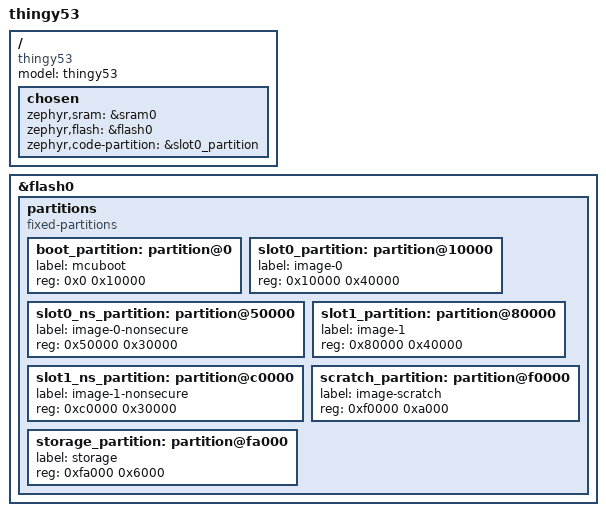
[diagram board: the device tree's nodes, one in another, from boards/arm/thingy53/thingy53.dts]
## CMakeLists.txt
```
#
# Copyright (c) 2019 Nordic Semiconductor ASA
#
# SPDX-License-Identifier: LicenseRef-Nordic-5-Clause
#
cmake_minimum_required(VERSION 3.20.0)

set(PM_STATIC_YML_FILE
  ${CMAKE_CURRENT_SOURCE_DIR}/boards/pm_static_${BOARD}.yml
  )

find_package(Zephyr REQUIRED HINTS $ENV{ZEPHYR_BASE})
project(bdi-coap-client)


FILE(GLOB APP_SOURCES src/main.cpp
         src/coap/CoapClient.cpp
         src/mas-abstractions/organization/Organization.cpp
         src/mas-abstractions/agent/ReactiveAgent.cpp
         src/thread/thread_helper.c
         src/peripherals/gpio.c
         src/low_power.c
         src/observer.c)

#FILE(GLOB EMB_BDI_AGENT_SOURCES embedded-bdi/lib/agent/*.cpp)
#FILE(GLOB EMB_BDI_BDI_SOURCES embedded-bdi/lib/bdi/*.cpp)
#FILE(GLOB EMB_BDI_LIB_SOURCES embedded-bdi/lib/lib/*.cpp)
#FILE(GLOB EMB_BDI_SYNTAX_SOURCES embedded-bdi/lib/syntax/*.cpp)

# NORDIC SDK APP START

# Using Embedded BDI (Uncomment following two lines)
#target_sources(app PRIVATE ${APP_SOURCES} ${EMB_BDI_AGENT_SOURCES} ${EMB_BDI_BDI_SOURCES} ${EMB_BDI_LIB_SOURCES} ${EMB_BDI_SYNTAX_SOURCES})
#target_include_directories(app PRIVATE src embedded-bdi embedded-bdi/lib interface)

# Using Reactive Agent
target_sources(app PRIVATE ${APP_SOURCES})
target_include_directories(app PRIVATE src interface)


# Preinitialization related to Thingy:53 DFU
#target_sources_ifdef(CONFIG_BOARD_THINGY53_NRF5340_CPUAPP app PRIVATE
#  boards/thingy53.c
#)
#target_sources_ifdef(CONFIG_BOARD_THINGY53_NRF5340_CPUAPP_NS app PRIVATE
#  boards/thingy53.c
#)

# NORDIC SDK APP END

target_sources_ifdef(CONFIG_BT_NUS app PRIVATE src/ble_utils.c)
zephyr_library_include_directories(.)
```

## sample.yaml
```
sample:
  description: Thingy:53 BDI CoAP Client Application
  name: Thingy:53 BDI CoAP Client
tests:
  applications.openthread.thingy53-bdi-coap-client:
    build_only: true
    integration_platforms:
      - thingy53_nrf5340_cpuapp
      - thingy53_nrf5340_cpuapp_ns
    platform_allow: thingy53_nrf5340_cpuapp thingy53_nrf5340_cpuapp_ns
    tags: openthread ci_build
```

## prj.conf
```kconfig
################################################################################
# Nordic related
CONFIG_NCS_SAMPLES_DEFAULTS=n
# nRF board library
CONFIG_DK_LIBRARY=y
#CONFIG_OPENTHREAD_NORDIC_LIBRARY_MASTER=y

################################################################################
# Logging related
#CONFIG_SERIAL=n
CONFIG_LOG=y
CONFIG_CONSOLE=y
CONFIG_UART_CONSOLE=y
CONFIG_RTT_CONSOLE=y
CONFIG_USE_SEGGER_RTT=y
CONFIG_PRINTK=y
CONFIG_LOG_MODE_IMMEDIATE=n
CONFIG_STDOUT_CONSOLE=y
#CONFIG_SHELL_BACKEND_RTT=y

################################################################################
# PM related 
#Low power config
#CONFIG_PM=y
CONFIG_PM_DEVICE=y
CONFIG_CRC=y
CONFIG_POWEROFF=y

# Network shell
#CONFIG_SHELL=y
#CONFIG_OPENTHREAD_SHELL=y
#CONFIG_SHELL_ARGC_MAX=26
#CONFIG_SHELL_CMD_BUFF_SIZE=416

# Network sockets
CONFIG_NET_SOCKETS=y
CONFIG_NET_SOCKETS_POSIX_NAMES=y
CONFIG_NET_SOCKETS_POLL_MAX=4

#######################################################################
CONFIG_BT=y
CONFIG_BT_OBSERVER=y

################################################################################
#OpenThread related --------------------------------------------------------------
# Same network Master Key for client and server
CONFIG_OPENTHREAD_NETWORKKEY="00:11:22:33:44:55:66:77:88:99:aa:bb:cc:dd:ee:ff"
# L2 OpenThread enabling
CONFIG_NET_L2_OPENTHREAD=y
# Generic networking options
CONFIG_NETWORKING=y
CONFIG_OPENTHREAD_SHELL=n
CONFIG_OPENTHREAD_MTD=y
CONFIG_OPENTHREAD_MTD_SED=y
CONFIG_OPENTHREAD_POLL_PERIOD=3000

#CONFIG_OPENTHREAD_MTD = y
#CONFIG_OPENTHREAD = y
#CONFIG_OPENTHREAD_MTD_SED=y
#CONFIG_OPENTHREAD_POLL_PERIOD=600000
# Enable OpenThread CoAP support API
CONFIG_OPENTHREAD_COAP=y
#CONFIG_COAP_UTILS=y
CONFIG_OPENTHREAD_COAP_BLOCK=y
CONFIG_OPENTHREAD_COAP_OBSERVE=y
#CONFIG_COAP_CLIENT_LOG_LEVEL_DBG=y
#CONFIG_COAP_CLIENT_UTILS_LOG_LEVEL_DBG=y
#CONFIG_COAP_UTILS_LOG_LEVEL_DBG=y
CONFIG_OPENTHREAD_LOG_LEVEL_NOTE=y
CONFIG_OPENTHREAD_DEBUG=y

################################################################################
CONFIG_ASSERT=y
CONFIG_ASSERT_NO_COND_INFO=y
CONFIG_MBEDTLS_SHA1_C=n
CONFIG_FPU=y

CONFIG_NEWLIB_LIBC=y
CONFIG_CPLUSPLUS=y
CONFIG_STD_CPP20=n
CONFIG_LIB_CPLUSPLUS=y


################################################################################
# Stack configuration

CONFIG_HEAP_MEM_POOL_SIZE=3600
CONFIG_SYSTEM_WORKQUEUE_STACK_SIZE=4096
CONFIG_MAIN_STACK_SIZE=4096

################################################################################
# Sensor configuration

# Enable BME688 Sensor
CONFIG_BME680=y
CONFIG_I2C=y
CONFIG_SPI=y
CONFIG_SENSOR=y
CONFIG_CBPRINTF_FP_SUPPORT=y
# Disable nRF5 sensor
CONFIG_TEMP_NRF5=n
# Battery Options
#CONFIG_ADC=y

################################################################################
# Extra libraries
CONFIG_JSON_LIBRARY=y
```

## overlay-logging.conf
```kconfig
#
# Copyright (c) 2022 Nordic Semiconductor
#
# SPDX-License-Identifier: LicenseRef-Nordic-5-Clause

# Enable net module logging
CONFIG_NET_LOG=y
# Option for configuring log level in net config library
CONFIG_NET_CONFIG_LOG_LEVEL_INF=y

# Option for configuring log level in Zephyr L2 logging
CONFIG_OPENTHREAD_L2_DEBUG=y
CONFIG_OPENTHREAD_L2_LOG_LEVEL_DBG=y
CONFIG_OPENTHREAD_L2_DEBUG_DUMP_15_4=y
CONFIG_OPENTHREAD_L2_DEBUG_DUMP_IPV6=y

# Option for configuring log level in OpenThread
CONFIG_OPENTHREAD_LOG_LEVEL_INFO=y
```

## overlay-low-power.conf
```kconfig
#
# Copyright (c) 2022 Nordic Semiconductor
#
# SPDX-License-Identifier: LicenseRef-Nordic-5-Clause
#

CONFIG_LOG=n
CONFIG_PRINTK=n
CONFIG_OPENTHREAD_NORDIC_LIBRARY_MTD=y
CONFIG_OPENTHREAD_MTD=y
CONFIG_RAM_POWER_DOWN_LIBRARY=y
CONFIG_PM_DEVICE=y

CONFIG_SYSTEM_WORKQUEUE_STACK_SIZE=2048
```

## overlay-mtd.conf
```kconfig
#
# Copyright (c) 2020 Nordic Semiconductor
#
# SPDX-License-Identifier: LicenseRef-Nordic-5-Clause
#

# Enable MTD Sleepy End Device
CONFIG_OPENTHREAD_MTD=y
CONFIG_OPENTHREAD_MTD_SED=y
CONFIG_OPENTHREAD_POLL_PERIOD=3000
CONFIG_RAM_POWER_DOWN_LIBRARY=y
CONFIG_PM_DEVICE=y
```

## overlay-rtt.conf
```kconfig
#
# Copyright (c) 2022 Nordic Semiconductor
#
# SPDX-License-Identifier: LicenseRef-Nordic-5-Clause
#

# Disable RTT logging backend
CONFIG_USE_SEGGER_RTT=y
CONFIG_LOG_BACKEND_RTT=y

# Enable UART logging backend
CONFIG_LOG_BACKEND_UART=n
CONFIG_SHELL_LOG_BACKEND=n
```

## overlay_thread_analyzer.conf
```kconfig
#
# Copyright (c) 2020 Nordic Semiconductor
#
# SPDX-License-Identifier: LicenseRef-Nordic-5-Clause
#
#


# In order to correctly tune the stack sizes for the threads the following
# Configurations can enabled to print the current use:
CONFIG_THREAD_NAME=y
CONFIG_THREAD_ANALYZER=y
CONFIG_THREAD_ANALYZER_AUTO=y
CONFIG_THREAD_ANALYZER_RUN_UNLOCKED=y
CONFIG_THREAD_ANALYZER_USE_PRINTK=y
CONFIG_CONSOLE=y
CONFIG_UART_CONSOLE=y
CONFIG_SERIAL=y
CONFIG_PRINTK=y
```

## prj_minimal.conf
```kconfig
#
# Copyright (c) 2020 Nordic Semiconductor
#
# SPDX-License-Identifier: LicenseRef-Nordic-5-Clause
#
#
CONFIG_NCS_SAMPLES_DEFAULTS=y
# nRF board library
CONFIG_DK_LIBRARY=y

# Enable OpenThread CoAP support API
CONFIG_OPENTHREAD_COAP=y
#CONFIG_COAP_UTILS=y
CONFIG_OPENTHREAD_COAP_BLOCK=y
CONFIG_OPENTHREAD_COAP_OBSERVE=y

# Configure sample logging setting
CONFIG_LOG=n
CONFIG_COAP_CLIENT_LOG_LEVEL_DBG=n
CONFIG_COAP_CLIENT_UTILS_LOG_LEVEL_DBG=n
#CONFIG_COAP_UTILS_LOG_LEVEL_DBG=y
CONFIG_OPENTHREAD_LOG_LEVEL_NOTE=n
CONFIG_OPENTHREAD_DEBUG=n

# Adjust log strdup settings

# Network shell
CONFIG_SHELL=y
CONFIG_OPENTHREAD_SHELL=y
CONFIG_SHELL_ARGC_MAX=26
CONFIG_SHELL_CMD_BUFF_SIZE=416

# Network sockets
CONFIG_NET_SOCKETS=y
CONFIG_NET_SOCKETS_POSIX_NAMES=y
CONFIG_NET_SOCKETS_POLL_MAX=4

# Same network Master Key for client and server
CONFIG_OPENTHREAD_NETWORKKEY="00:11:22:33:44:55:66:77:88:99:aa:bb:cc:dd:ee:ff"

# L2 OpenThread enabling
CONFIG_NET_L2_OPENTHREAD=y

# Generic networking options
CONFIG_NETWORKING=y

CONFIG_ASSERT=y
CONFIG_ASSERT_NO_COND_INFO=y
CONFIG_MBEDTLS_SHA1_C=n
CONFIG_FPU=y

CONFIG_PRINTK=y
CONFIG_NEWLIB_LIBC=y
CONFIG_CPLUSPLUS=y
CONFIG_STD_CPP20=n
CONFIG_LIB_CPLUSPLUS=y


################################################################################
# Stack configuration

CONFIG_HEAP_MEM_POOL_SIZE=3600
CONFIG_SYSTEM_WORKQUEUE_STACK_SIZE=4096
CONFIG_MAIN_STACK_SIZE=4096

################################################################################
# Sensor configuration

# Enable BME688 Sensor
CONFIG_BME680=y

CONFIG_I2C=y
CONFIG_SPI=y
CONFIG_SENSOR=y
CONFIG_CBPRINTF_FP_SUPPORT=y

# Disable nRF5 sensor
CONFIG_TEMP_NRF5=n

# Battery Options
#CONFIG_ADC=y

################################################################################
# PM related 
#Low power config
#CONFIG_PM=y
CONFIG_PM_DEVICE=y
CONFIG_CRC=y
CONFIG_POWEROFF=y

################################################################################
# Extra libraries
CONFIG_JSON_LIBRARY=y
```

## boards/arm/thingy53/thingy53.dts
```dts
// Copyright (c) 2023 Nordic Semiconductor ASA
// SPDX-License-Identifier: Apache-2.0

/dts-v1/;
#include <nordic/nrf5340_cpuapp_qkaa.dtsi>

/ {
	model = "thingy53";
	compatible = "thingy53";

	chosen {
		zephyr,sram = &sram0;
		zephyr,flash = &flash0;
		zephyr,code-partition = &slot0_partition;
	};
};

&flash0 {
	partitions {
		compatible = "fixed-partitions";
		#address-cells = <1>;
		#size-cells = <1>;

		boot_partition: partition@0 {
			label = "mcuboot";
			reg = <0x0 0x10000>;
		};
		slot0_partition: partition@10000 {
			label = "image-0";
			reg = <0x10000 0x40000>;
		};
		slot0_ns_partition: partition@50000 {
			label = "image-0-nonsecure";
			reg = <0x50000 0x30000>;
		};
		slot1_partition: partition@80000 {
			label = "image-1";
			reg = <0x80000 0x40000>;
		};
		slot1_ns_partition: partition@c0000 {
			label = "image-1-nonsecure";
			reg = <0xc0000 0x30000>;
		};
		scratch_partition: partition@f0000 {
			label = "image-scratch";
			reg = <0xf0000 0xa000>;
		};
		storage_partition: partition@fa000 {
			label = "storage";
			reg = <0xfa000 0x6000>;
		};
	};
};
```

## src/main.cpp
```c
/**
 * Thing:53 BDI CoAP Client
 *
 * main.cpp
 */

#include <dk_buttons_and_leds.h>
#include <ram_pwrdn.h>
#include <zephyr/pm/device.h>
#include <zephyr/pm/pm.h>
//#include <zephyr/drivers/gpio.h>
#include <zephyr/sys/poweroff.h>
#include <ram_pwrdn.h>

#include "main.h"
#include "mas-abstractions/organization/Organization.h"
#include "mas-abstractions/agent/ReactiveAgent.h"

#define CONFIG_THINGY_LOW_POWER
//#define CONFIG_THINGY_USE_SENSOR
#if defined(CONFIG_THINGY_LOW_POWER)
#include "low_power.h"
#endif

#include <zephyr/bluetooth/bluetooth.h>
#include "observer.c"

LOG_MODULE_REGISTER(main, CONFIG_COAP_CLIENT_LOG_LEVEL);

//#define GPIO0_NODE DT_NODELABEL(gpio0)
//#define PIN 9

/**************************************************************************************************
  Agent ID string.
**************************************************************************************************/
std::string agent_id = "agent-" + std::to_string(AGENT_ID);

/**************************************************************************************************
  LED defines.
**************************************************************************************************/
#define RED_LED				DK_LED1
#define GREEN_LED			DK_LED2
#define BLUE_LED			DK_LED3


/**************************************************************************************************
  Variables for BDI-reasoner
**************************************************************************************************/
int32_t agent_period = DEFAULT_AGENT_PERIOD;
//

/**************************************************************************************************
  Global Variables.
**************************************************************************************************/

/**************************************************************************************************
  CoAP Variables.
**************************************************************************************************/
#ifdef CONFIG_THINGY_USE_SENSOR
BME688* m_p_bme_sensor;
#endif
#ifdef USE_EMB_BDI
	Agent* m_p_sensor_agent;
#else
	ReactiveAgent* m_p_sensor_agent;
#endif
/**************************************************************************************************
  Thread Declarations.
**************************************************************************************************/

/**************************************************************************************************
  Embedded BDI Agent Thread Declaration.
**************************************************************************************************/
void agent_run_thread_cb(void);
K_THREAD_DEFINE(agent_run_thread_id, STACKSIZE, agent_run_thread_cb, NULL, NULL, NULL, 
					AGENT_PRIORITY, 0, 0);

/**************************************************************************************************
  Measurement Thread Declaration.
**************************************************************************************************/
void sensing_thread_cb(void);
K_THREAD_DEFINE(sensing_thread_id, SENSING_STACKSIZE, sensing_thread_cb, NULL, NULL, NULL, 
					SENSOR_PRIORITY, 0, 0);

/**************************************************************************************************
  Transmission Thread Declaration.
**************************************************************************************************/
void transmission_thread_cb(void);
K_THREAD_DEFINE(transmission_thread_id, TRANSMISSION_STACKSIZE, transmission_thread_cb, NULL, NULL, NULL, 
					TRANSMISSION_PRIORITY, 0, 0);


/**************************************************************************************************
  BDI Callback-Functions.
**************************************************************************************************/


/**************************************************************************************************
  OpenThread Callback-Functions.
**************************************************************************************************/

/**************************************************************************************************
  Toggles MED and SED mode when enabled in build.
**************************************************************************************************/
//typedef struct otLinkModeConfig
//{
//    bool mRxOnWhenIdle : 1; ///< 1, if the sender has its receiver on when not transmitting. 0, otherwise.
//    bool mDeviceType : 1;   ///< 1, if the sender is an FTD. 0, otherwise.
//    bool mNetworkData : 1;  ///< 1, if the sender requires the full Network Data. 0, otherwise.
//}

static void on_mtd_mode_toggle(/*uint32_t med*/otLinkModeConfig mode)
{
#if IS_ENABLED(CONFIG_PM_DEVICE)
	const struct device *cons = DEVICE_DT_GET(DT_CHOSEN(zephyr_console));

	if (!device_is_ready(cons)) {
		return;
	}
	uint32_t rxon = mode.mRxOnWhenIdle;
	uint32_t ftd = mode.mDeviceType;
	dk_set_led_off(BLUE_LED);
	dk_set_led_off(RED_LED);
	dk_set_led_off(GREEN_LED);
	if (rxon || ftd) {
		// pm_device_action_run(cons, PM_DEVICE_ACTION_RESUME);
		dk_set_led_on(RED_LED);
	} else {
		// pm_device_action_run(cons, PM_DEVICE_ACTION_SUSPEND);
		dk_set_led_on(GREEN_LED);
	}
#endif
	
}

/**************************************************************************************************
  Button Actions.
**************************************************************************************************/
static bool in_role = false;
static void on_button_changed(uint32_t button_state, uint32_t has_changed)
{
	uint32_t buttons = button_state & has_changed;
	if ((buttons & DK_BTN1_MSK) && has_changed==1) {
		dk_set_led_off(BLUE_LED);
		dk_set_led_off(RED_LED);
		dk_set_led_off(GREEN_LED);

		
		//LOG_INF("Creating organization entity object %d", 2);
		if(in_role){
			Organization::leaveRole("rl-1");
			dk_set_led_on(RED_LED);
			in_role = false;
		}else{
			Organization::joinRole("rl-1", 100);
			dk_set_led_on(GREEN_LED);
			in_role = true;
		}
		//Organization::sendMeasurement("gr_test_role", 12.1);
	}else if (buttons & DK_BTN2_MSK) {
		// Nothing

	}
}

/**************************************************************************************************
  Sensor Semaphore.
**************************************************************************************************/
K_SEM_DEFINE(sensor_sem, 0, 1);

/**************************************************************************************************
  Sensing Thread. Lower number -> higher prio
**************************************************************************************************/
void sensing_thread_cb(void)
{
	k_sleep(K_FOREVER);
	/* Run sensing loop */
	while(true){
		/* Sleep as long as no role is assigned */
		//LOG_INF("%i: Sensing Thread...\n", log_iterator++);
		/* Read BME688 enviromental sensor */		
		#ifdef CONFIG_THINGY_USE_SENSOR
		m_p_bme_sensor->measure();

		/* Release transmission when buffer is full */
		if (m_p_bme_sensor->isBufferFull())
		{ 
			k_sem_give(&sensor_sem);
		}
		#endif
		/* sleep */
		//k_sleep(1000 /*roles[current_role].getMeasurementPeriod()*/);
	}
}

/**************************************************************************************************
  Transmission Thread.
**************************************************************************************************/
void transmission_thread_cb(void)
{
	//k_sleep(K_FOREVER);
	/* Run transmission loop */
	while(true){
		/* Transmit to Server */
		k_sem_take(&sensor_sem, K_FOREVER); //Add timeout to prevent deadlock...
		//LOG_INF("%i: Transmit sensor data:\n---> %s\n", log_iterator++, m_p_bme_sensor->getPayload() .c_str());

		/* Reset buffer */
		#ifdef CONFIG_THINGY_USE_SENSOR
		m_p_bme_sensor->clearBuffer();
		#endif
		/* sleep */
		k_sleep(K_FOREVER);
	}
}

/**************************************************************************************************
  Embedded BDI Agent Thread.
**************************************************************************************************/
void agent_run_thread_cb(void)
{
	k_sleep(K_FOREVER);
	while(true){
		LOG_INF("%s","Waking agent..");
		dk_set_led_off(BLUE_LED);
		dk_set_led_off(RED_LED);
		dk_set_led_on(GREEN_LED);
		m_p_sensor_agent->run();
		k_msleep(agent_period);
	}
}

/**************************************************************************************************
  Main Function.
**************************************************************************************************/
int main(void)
{
	LOG_INF("%i: Start Thingy:53 BDI CoAP Client...\n", log_iterator++);

	int ret;
	#if USE_GPIO_OUTPUT
		/* Initialize GPIOs */
		ret = gpio_output_init();
		if (ret) {
			LOG_ERR("Cannot init gpios, (error: %d)", ret);
			return 0;
		}
		gpio_pin_set_dt(&out0, 0);
		gpio_pin_set_dt(&out1, 0);
		gpio_pin_set_dt(&out2, 0);
	#endif /* USE_GPIO_OUTPUT */



	//struct otInstance *openthread = openthread_get_default_instance();
	//struct net_if * net = net_if_get_default();

	/* Enabled if built as sleepy end device */
	if (IS_ENABLED(CONFIG_RAM_POWER_DOWN_LIBRARY)) {
		//power_down_unused_ram();
	}

	/* Initialize buttons */
	ret = dk_buttons_init(on_button_changed);
	if (ret) {
		LOG_ERR("Cannot init buttons (error: %d)", ret);
		return 0;
	}

	/* Initialize LEDs */
	ret = dk_leds_init();
	if (ret) {
		LOG_ERR("Cannot init leds, (error: %d)", ret);
		return 0;
	}

	/* Initialize Sensor object*/
	#ifdef CONFIG_THINGY_USE_SENSOR
	m_p_bme_sensor = new BME688(agent_id);
	#endif
	m_p_sensor_agent = new ReactiveAgent();
	/* Initialize battery measurement */
	//ret = battery_measure_enable(true);
	//if (ret) {
	//	LOG_ERR("Failed initialize battery measurement (error: %d)", ret);
	//	return 0;
	//}

	LOG_INF("Creating CoAP channel %d",1);
	//LOG_INF("CoAP channel initialized. Response=%d", resp);
	dk_set_led_off(BLUE_LED);
	dk_set_led_off(RED_LED);
	dk_set_led_off(GREEN_LED);
	startThread(on_mtd_mode_toggle);	
	k_sleep(K_MSEC(2000));



	
	CoapClient::initialize();
	//dk_set_led_on(BLUE_LED);
	//k_sleep(K_MSEC(2000));
	//dk_set_led_off(BLUE_LED);
	//dk_set_led_off(RED_LED);
	//dk_set_led_off(GREEN_LED);


	printk("Starting Observer Demo\n");

	/* Initialize the Bluetooth Subsystem */
	int err = bt_enable(NULL);
	if (err) {
		printk("Bluetooth init failed (err %d)\n", err);
		return 0;
	}

	(void)observer_start();

#if defined(CONFIG_THINGY_LOW_POWER)
	//low_power_enable();
#endif


	while(true){
		dk_set_led_on(BLUE_LED);
		k_sleep(K_MSEC(500));
		dk_set_led_off(BLUE_LED);
		//k_sleep(K_MSEC(500));
		//dk_set_led_off(BLUE_LED);
		//dk_set_led_off(RED_LED);

		//dk_set_led_off(GREEN_LED);
			
		//gpio_output_set(9,1); //Trace to mark energy measurement start	
		Organization::refresh();
		//m_p_sensor_agent->run();S
		k_sleep(K_MSEC(1000));
		LOG_INF("ding %d ",1);
		printk("ding..");
	}

}
```

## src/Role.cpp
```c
#include "Role.h"
/**************************************************************************************************
  Role Class.
**************************************************************************************************/
Role::Role(int role_number, const char *org_spec, std::string agent_id) {
	get_group_and_role_id(role_number, &m_group_id, &m_role_id, &m_group_number, org_spec);
	m_role_number = role_number;
	get_role_property(m_role_id, "update_period", &m_update_period, org_spec);
	get_role_property(m_role_id, "measurement_period", &m_measurement_period, org_spec);
	get_group_spec(m_role_id, "min", &m_min_agents, org_spec);
	m_workload_divider = 1;
	m_role_costs = 0;
	reevaluateRoleCosts(false,1);
    m_agent_id = agent_id;
}

void Role::setOrgSpecReward(int reward)
{
	m_org_spec_reward = reward;
	return;
}

void Role::reevaluateRoleCosts(bool override, int battery)
{    
    if(!override){
		//update_battery_level(&m_battery_level);
	}else{
		m_battery_level = battery;
	}
	/* Lower Frequency */
	if (30 < m_measurement_period) {
		m_role_costs = m_battery_level == 1 ? -1 : 0;
	}
	else if (m_measurement_period <= 30) {
		m_role_costs = m_battery_level == 1 ? 0 : 2;
	}
	return;
}

void Role::setWorkloadDivider(int number_of_agents)
{
	m_workload_divider = number_of_agents;
	return;
}

int Role::getTotalCostReward()
{
	return m_org_spec_reward-m_role_costs;
}

int Role::getRoleNumber()
{
	return m_role_number;
}

std::string Role::getRoleId()
{
	return m_role_id;
}

std::string Role::getRoleUri()
{
	std::string uri = "org-entities/oe-groups/gr_0" + std::to_string(m_group_number) + "_" +
	m_group_id + "/gr_0" + std::to_string(m_group_number) + "_" + m_group_id + "_" + m_role_id;
	return uri;
}

std::string Role::getRolePlayerUri()
{
	std::string uri = "org-entities/oe-groups/gr_0" + std::to_string(m_group_number) + "_" +
	m_group_id + "/gr_0" + std::to_string(m_group_number) + "_" + m_group_id + "_" + m_role_id;
	
	uri = uri + "/" + "rp_" + m_agent_id + "_gr_0" + std::to_string(m_group_number) + "_" +
	m_group_id + "_" + m_role_id;
	return uri;
}

int Role::getBufferSize(){
	return m_update_period/m_measurement_period;
}

k_timeout_t Role::getMeasurementPeriod(){
	return K_MSEC(m_workload_divider*m_measurement_period*1000);
}

int Role::getWorkloadDivider()
{
	return m_workload_divider;
}
```

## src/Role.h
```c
#ifndef ROLE2_H
#define ROLE2_H

#include <stdio.h>
#include <stdlib.h>
#include <unistd.h>
#include <vector>
#include <array>
#include <string>
#include <iostream>
#include <math.h>
#include <numeric>
#include <algorithm>

/**************************************************************************************************
  ZEPHYR include files.
**************************************************************************************************/
#include <zephyr/kernel.h>



/**************************************************************************************************
  Task include files.
**************************************************************************************************/
#include "agent/agent.h"
#include "config/configuration.h"
#include "bdi-agent/functions.h"
#include "parse_xml.h"
#include <coap_server_client_interface.h>

extern "C" {
  #include "coap_client_utils.h"
  //#include "sensors.h"
  //#include "battery.h"
  //#include "gpio.h"
}

/**************************************************************************************************
  Role Class.
**************************************************************************************************/
class Role {
	private:
		std::string m_group_id;
		std::string m_role_id;
		int m_group_number;
		int m_role_number;
		int m_measurement_period;
		int m_update_period;
		int m_role_costs;
		int m_org_spec_reward;
		int m_min_agents;
		int m_workload_divider;
        int m_battery_level = 1;
        std::string m_agent_id;

	public:
		Role(int role_number, const char *org_spec, std::string agent_id);
		void setOrgSpecReward(int reward);
		void reevaluateRoleCosts(bool override, int battery);
		void setWorkloadDivider(int number_of_agents);
		std::string getRoleId();
		int getRoleNumber();
		std::string getRoleUri();
		std::string getRolePlayerUri();
		int getTotalCostReward();
		int getBufferSize();
		int getWorkloadDivider();
		k_timeout_t getMeasurementPeriod();
};
#endif
```

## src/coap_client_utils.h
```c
/**
 * coap_client_utils.h
 */

#ifndef __COAP_CLIENT_UTILS_H__
#define __COAP_CLIENT_UTILS_H__

#include <coap_server_client_interface.h>

/** @brief Type indicates function called when OpenThread connection
 *         is established.
 *
 * @param[in] item pointer to work item.
 */
typedef void (*ot_connection_cb_t)(struct k_work *item);

/** @brief Type indicates function called when OpenThread connection is ended.
 *
 * @param[in] item pointer to work item.
 */
typedef void (*ot_disconnection_cb_t)(struct k_work *item);

/** @brief Type indicates function called when the MTD modes are toggled.
 *
 * @param[in] val 1 if the MTD is in MED mode
 *                0 if the MTD is in SED mode
 */
typedef void (*mtd_mode_toggle_cb_t)(uint32_t val);

typedef void (*get_org_spec_xml_cb_t)(uint8_t *data, uint16_t size, uint8_t xml_part, uint8_t total_xml_parts);

typedef void (*post_role_cb_t)(bool created);

typedef void (*delete_role_cb_t)(bool success);

typedef void (*get_reward_cb_t)(int reward, const char *role_id, bool role_player);


/** @brief Initialize CoAP client utilities.
 */
int coap_client_utils_init(ot_connection_cb_t on_connect,
			    ot_disconnection_cb_t on_disconnect,
			    mtd_mode_toggle_cb_t on_toggle,
				get_org_spec_xml_cb_t on_get_xml,
				post_role_cb_t on_post_role,
				delete_role_cb_t on_delete_role,
				get_reward_cb_t on_get_reward);

/**************************************************************************************************
  Initializes GET organizational specification XML request to CoAP server.
**************************************************************************************************/
void coap_client_get_xml(void);
/**************************************************************************************************
  Initializes GET organizational specification XML request to CoAP server.
**************************************************************************************************/
void coap_client_get_xml_segments(const char *uri, const char *query);

/**************************************************************************************************
  Initializes GET BME688 server data request.
**************************************************************************************************/
void coap_client_get_bme688(uint8_t agent_id, uint8_t sensor);

/**************************************************************************************************
  Initializes PUT BME688 server data buffer request.
**************************************************************************************************/
void coap_client_put_bme688(const char *uri, const char *bme688_data);

void coap_client_post_role(const char *uri, const char *agent_id_str, size_t agent_id_len);

void coap_client_delete_role(const char *uri);

void coap_client_get_reward(const char *uri);

/** @brief PUT BME688 sensor data buffer on the CoAP server.
 */
void submit_coap_request(const char *uri, uint8_t coap_code, uint8_t coap_type,
								 uint32_t observe, const char *payload, size_t payload_size);

/** @brief Toggle SED to MED and MED to SED modes.
 *
 * @note Active when the device is working as Minimal Thread Device.
 */
void coap_client_toggle_minimal_sleepy_end_device(void);

#endif

/**
 * @}
 */
```

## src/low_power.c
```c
/*
 * Copyright (c) 2023 Nordic Semiconductor ASA
 *
 * SPDX-License-Identifier: LicenseRef-Nordic-5-Clause
 */

#include <openthread/thread.h>
#include <zephyr/net/openthread.h>
#include <zephyr/device.h>
#include <zephyr/pm/device.h>
//#include <ram_pwrdn.h>

#include "low_power.h"

static void on_thread_state_changed(otChangedFlags flags, struct openthread_context *ot_context,
				    void *user_data)
{
	if (flags & OT_CHANGED_THREAD_ROLE) {
		if (otThreadGetDeviceRole(ot_context->instance) == OT_DEVICE_ROLE_CHILD) {
			const struct device *cons = DEVICE_DT_GET(DT_CHOSEN(zephyr_console));

			if (!device_is_ready(cons)) {
				return;
			}

			//pm_device_action_run(cons, PM_DEVICE_ACTION_SUSPEND);
			//power_down_unused_ram();
		}
	}
}

static struct openthread_state_changed_cb ot_state_chaged_cb = {
	.state_changed_cb = on_thread_state_changed
};

void low_power_enable(void)
{
	openthread_state_changed_cb_register(openthread_get_default_context(), &ot_state_chaged_cb);
}
```

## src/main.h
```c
/**
 * main.h
 */

#ifndef MAIN_H
#define MAIN_H

#include <stdio.h>
#include <stdlib.h>
#include <unistd.h>
#include <vector>
#include <array>
#include <string>
#include <iostream>
#include <math.h>
#include <numeric>
#include <algorithm>
#include "peripherals/BME688.h"

/**************************************************************************************************
  ZEPHYR include files.
**************************************************************************************************/
#include <zephyr/kernel.h>
#include <zephyr/logging/log.h>
#include <zephyr/device.h>
#include <zephyr/devicetree.h>
#include <zephyr/drivers/gpio.h>
#include <zephyr/sys/printk.h>
#include <zephyr/drivers/sensor.h>
#include <openthread/coap.h>

/**************************************************************************************************
  Task include files.
**************************************************************************************************/
/**************************** Embedded BDI Agent ****************************/
#ifdef USE_EMB_BDI
#include "agent/agent.h"
#include "mas-abstractions/agent/bdi-agent/configuration.h"
#include "mas-abstractions/agent/bdi-agent/functions.h"
#endif
/****************************************************************************/

#include <coap_server_client_interface.h>

extern "C" {
  //#include "peripherals/sensors.h"
  //#include "peripherals/battery.h"
  #include "low_power.h"
  #include "peripherals/gpio.h"
  #include "thread/thread_helper.h"
}

/**************************************************************************************************
  Enable or disable parts of the code.
**************************************************************************************************/
#define LOW_POWER						   0
#define USE_GPIO_OUTPUT					   1

/**************************************************************************************************
  Defines.
**************************************************************************************************/
/* Size of stack area used by each thread */
#define STACKSIZE             			4096
#define TRANSMISSION_STACKSIZE          1024
#define SENSING_STACKSIZE          		1024

/* Scheduling priority used by agent thread */
#define AGENT_PRIORITY           		   7

/* Scheduling priority used by agent thread */
#define SENSOR_PRIORITY          		   7

/* Scheduling priority used by agent thread */
#define TRANSMISSION_PRIORITY          	   6

/**************************************************************************************************
  Agent default properties.
**************************************************************************************************/
#define AGENT_ID                           3
#define REASONING_CYCLES                  50
#define DEFAULT_AGENT_PERIOD           5000
#define DEFAULT_SENSING_PERIOD_FACTOR      1
#define MAX_BUFFER_SIZE                   10

/**************************************************************************************************
  Properties to determine if role can be fullfilled.
**************************************************************************************************/
#define MINIMAL_SENSING_PERIOD             5
#define MINIMAL_TRANSMISSION_PERIOD        5

/**************************************************************************************************
  Constants for .xml parser.
**************************************************************************************************/
#define MAX_GOALS                         10
#define MAX_PROPERTIES                    10
#define MAX_ARGUMENTS                     10
#define MAX_ROLES                          3

/**************************************************************************************************
  Variables for BDI-reasoner.
**************************************************************************************************/
extern bool start_agent;
extern bool org_spec_changed;
extern bool rewards_changed;
extern bool local_capabilities_changed;
extern bool optimal_state;
extern bool role_assigned;
extern bool role_deleted;

extern bool role_available;
extern uint8_t iterations;
extern bool transmission_due;
extern int32_t agent_period;
extern uint8_t sensing_period_factor;
extern uint8_t current_buffer_size;
extern double temperature;
extern double delta_temperature;
extern bool ot_sed;
extern uint8_t battery_capacity;

#endif /* MAIN_H_ */
```

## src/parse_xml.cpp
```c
#include <iostream>
#include <vector>
#include <string>
#include <fstream>
#include <sstream>
#include <iomanip>
//#include "tinyxml2/tinyxml2.h"
#include "tinyxml2/tinyxml2.cpp"
#include <main.h>

// using namespace std;
// using namespace tinyxml2;

LOG_MODULE_REGISTER(parse_xml, CONFIG_COAP_CLIENT_LOG_LEVEL);

/*************************************************************************************************/
/*!
 *  \brief  Counts the number of roles in the org-spec XML file.
 *
 *  \param  org_spec: pointer to .xml char array.
 * 
 *  \return numer of roles if success, -1 otherwise.
 */
/*************************************************************************************************/
int count_roles(const char * org_spec)
{
    int i = -1;
    tinyxml2::XMLDocument doc;
    tinyxml2::XMLError eResult = doc.Parse(org_spec, strlen(org_spec));
    if (eResult != tinyxml2::XML_SUCCESS) return -1;

    /* Get root Element <organisational-specification> */
    tinyxml2::XMLNode* root = doc.RootElement();
    if (NULL != root) {

        /* Get Child <structural-specification> */
        tinyxml2::XMLElement * structuralSpec = root -> FirstChildElement("structural-specification");
        if (NULL != structuralSpec) {

            /* Get Child <role-definitions> */
            tinyxml2::XMLElement * roleDef = structuralSpec -> FirstChildElement("role-definitions");
            if (NULL != roleDef) {
                
                /* Get all <role> elements */
                tinyxml2::XMLElement * role = roleDef -> FirstChildElement("role");
                i = 0;
                while (role) {
                    i++;
                    role = role -> NextSiblingElement("role");

                }
            }
        }
    }
    if (i == -1){
        LOG_WRN("Unexpected XML structure!\n");
        return -1;
    }
    return i;
}

/*************************************************************************************************/
/*!
 *  \brief  Gets the role Id for a given role number.
 *
 *  \param  role_number: number of the role in the list.
 *  \param  role_id: pointer to a string where the ID gets stored.
 *  \param  org_spec: pointer to .xml char array.
 * 
 *  \return 0 if success, -1 otherwise.
 */
/*************************************************************************************************/
int get_role_id(int role_number, std::string *role_id, const char * org_spec)
{
    int i = -1;
    tinyxml2::XMLDocument doc;
    tinyxml2::XMLError eResult = doc.Parse(org_spec, strlen(org_spec));
    if (eResult != tinyxml2::XML_SUCCESS) return -1;

    *role_id = "";
    /* Get root Element <organisational-specification> */
    tinyxml2::XMLNode* root = doc.RootElement();
    if (NULL != root) {

        /* Get Child <structural-specification> */
        tinyxml2::XMLElement * structuralSpec = root -> FirstChildElement("structural-specification");
        if (NULL != structuralSpec) {

            /* Get Child <role-definitions> */
            tinyxml2::XMLElement * roleDef = structuralSpec -> FirstChildElement("role-definitions");
            if (NULL != roleDef) {
                
                /* Get all <role> elements */
                tinyxml2::XMLElement * role = roleDef -> FirstChildElement("role");
                i = 0;
                while (role) {

                    if (i == role_number){
                        *role_id = role->Attribute("id");
                    }
                    i++;
                    role = role -> NextSiblingElement("role");

                }
            }
        }
    }
    if (i == -1){
        LOG_WRN("Unexpected XML structure!\n");
        return -1;
    }
    if (*role_id == ""){
        LOG_WRN("Role not found!\n");
        return -1;
    }
    return 0;
}

/*************************************************************************************************/
/*!
 *  \brief  Returns the role ID, group ID and group number for a given role number.
 *
 *  \param  role_number: number of the role in the list.
 *  \param  group_id: pointer to a string where the group ID gets stored.
 *  \param  role_id: pointer to a string where the role ID gets stored.
 *  \param  group_number: pointer to an integer where the group number gets stored.
 *  \param  org_spec: pointer to .xml char array.
 * 
 *  \return 0 if success, -1 otherwise.
 */
/*************************************************************************************************/
int get_group_and_role_id(int role_number, std::string *group_id, std::string *role_id, int *group_number, const char *org_spec)
{
    tinyxml2::XMLDocument doc;
    tinyxml2::XMLError eResult = doc.Parse(org_spec, strlen(org_spec));
    if (eResult != tinyxml2::XML_SUCCESS) return -1;

    int i = -1;
    int j = -1;
    *role_id = "";
    *group_id = "";

    /* Get root Element <organisational-specification> */
    tinyxml2::XMLNode* root = doc.RootElement();
    if (NULL != root) {

        /* Get Child <structural-specification> */
        tinyxml2::XMLElement * structuralSpec = root -> FirstChildElement("structural-specification");
        if (NULL != structuralSpec) {

            /* Get Child <role-definitions> */
            tinyxml2::XMLElement * roleDef = structuralSpec -> FirstChildElement("role-definitions");
            
            /* Get Sibling <group-specification> */
            tinyxml2::XMLElement * groupSpec = roleDef -> NextSiblingElement("group-specification");
            i = 0;
            while(groupSpec) {

                /* Get Chile <roles> */
                tinyxml2::XMLElement * g_roles = groupSpec -> FirstChildElement("roles");
                if (NULL != g_roles) {
                    
                    /* Get all <role> elements */
                    tinyxml2::XMLElement * g_role = g_roles -> FirstChildElement("role");
                    j = 0;
                    while (g_role) {
                        if (j == role_number){
                            *role_id = g_role->Attribute("id");
                            *group_id = groupSpec->Attribute("id");
                            *group_number = i+1;
                        }
                        j++;
                        g_role = g_role -> NextSiblingElement("role");
                    }
                }
                i++;
                groupSpec = groupSpec -> NextSiblingElement("group-specification");
            }
        }
    }
    if (i == -1 || j == -1){
        LOG_WRN("Unexpected XML structure!\n");
        return -1;
    }
    if (*role_id == ""){
        LOG_WRN("Role not found!\n");
        return -1;
    }
    if (*group_id == ""){
        LOG_WRN("Group not found!\n");
        return -1;
    }
    return 0;
}

/*************************************************************************************************/
/*!
 *  \brief  Gets the value of a given property ID for a given role ID.
 *
 *  \param  role_id: role ID.
 *  \param  property_id: Property ID.
 *  \param  property_value: pointer to an integer where the value gets stored.
 *  \param  org_spec: pointer to .xml char array.
 * 
 *  \return 0 if success, -1 otherwise.
 */
/*************************************************************************************************/
int get_role_property(std::string role_id, std::string property_id, 
                      int *property_value, const char *org_spec)
{
    tinyxml2::XMLDocument doc;
    tinyxml2::XMLError eResult = doc.Parse(org_spec, strlen(org_spec));
    if (eResult != tinyxml2::XML_SUCCESS) return -1;

    *property_value = -1;
    /* Get root Element <organisational-specification> */
    tinyxml2::XMLNode* root = doc.RootElement();
    if (NULL != root) {

        /* Get Child <structural-specification> */
        tinyxml2::XMLElement * structuralSpec = root -> FirstChildElement("structural-specification");
        if (NULL != structuralSpec) {

            /* Get Child <role-definitions> */
            tinyxml2::XMLElement * roleDef = structuralSpec -> FirstChildElement("role-definitions");
            if (NULL != roleDef) {
                
                /* Get all <role> elements */
                tinyxml2::XMLElement * role = roleDef -> FirstChildElement("role");
                while (role) {
                    
                    //role->Attribute("id");
                    
                    /* Get Child <properties> */
                    tinyxml2::XMLElement * p_properties = role -> FirstChildElement("properties");
                    if (NULL != p_properties) {
                        
                        /* Get all <property> elements */
                        tinyxml2::XMLElement * p_property = p_properties -> FirstChildElement("property");
                        while (p_property) {
                            
                            if (role_id == role->Attribute("id") && property_id == p_property->Attribute("id")){
                                *property_value = p_property->IntAttribute("value");
                            }
                            p_property = p_property -> NextSiblingElement("property");
                        }
                    }
                    role = role -> NextSiblingElement("role");
                }
            }
        }
    }
    if (*property_value == -1){
        printf("Property not found!\n");
        return -1;
    }
    return 0;
}

int get_group_spec(std::string role_id, std::string attribute, int *value, const char *org_spec)
{
    tinyxml2::XMLDocument doc;
    tinyxml2::XMLError eResult = doc.Parse(org_spec, strlen(org_spec));
    if (eResult != tinyxml2::XML_SUCCESS) return -1;

    *value = -1;

    /* Get root Element <organisational-specification> */
    tinyxml2::XMLNode* root = doc.RootElement();
    if (NULL != root) {

        /* Get Child <structural-specification> */
        tinyxml2::XMLElement * structuralSpec = root -> FirstChildElement("structural-specification");
        if (NULL != structuralSpec) {

            /* Get Child <role-definitions> */
            tinyxml2::XMLElement * roleDef = structuralSpec -> FirstChildElement("role-definitions");
            
            /* Get Sibling <group-specification> */
            tinyxml2::XMLElement * groupSpec = roleDef -> NextSiblingElement("group-specification");
            if (NULL != groupSpec) {

                /* Get Chile <roles> */
                tinyxml2::XMLElement * g_roles = groupSpec -> FirstChildElement("roles");
                if (NULL != g_roles) {
                    
                    /* Get all <role> elements */
                    tinyxml2::XMLElement * g_role = g_roles -> FirstChildElement("role");
                    while (g_role) {
                        if (role_id == g_role->Attribute("id") && attribute == "min"){
                                *value = g_role->IntAttribute("min");
                        }
                        if (role_id == g_role->Attribute("id") && attribute == "max"){
                                *value = g_role->IntAttribute("max");
                        }
                        g_role = g_role -> NextSiblingElement("role");
                    }
                }
            }
        }
    }
    if (*value == -1){
        printf("Attribute not found!\n");
        return -1;
    }
    return 0;
}
```

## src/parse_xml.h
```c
#ifndef PARSE_XML_H_
#define PARSE_XML_H_


/**************************************************************************************************
  Includes.
**************************************************************************************************/
#include <stdio.h>
#include <unistd.h>

int get_role_id(int role_number, std::string *role_id, const char * org_spec);

int get_group_and_role_id(int role_number, std::string *group_id, std::string *role_id, int *group_number, const char * org_spec);

int parse_xml(struct agent_role *agent_roles, const char *org_spec);

int count_roles(const char * org_spec);

int parse_test(const char * org_spec, size_t org_spec_lenght);

int get_role_property(std::string role_id, std::string property_id, int *property_value, const char *org_spec);

int get_group_spec(std::string role_id, std::string attribute, int *value, const char *org_spec);

#endif /* PARSE_XML_H_ */
```

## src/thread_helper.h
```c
#ifndef __THREAD_HELPER_H__
#define __THREAD_HELPER_H__

#include <stdio.h>
#include <zephyr/kernel.h>
#include <net/coap_utils.h>
#include <zephyr/logging/log.h>
#include <zephyr/net/openthread.h>
#include <openthread/thread.h>


typedef void (*thread_mode_change_cb_t)(uint32_t val);



otLinkModeConfig getCurrentMode(void);
void setCurrentMode(otLinkModeConfig mode);
void on_thread_state_changed(uint32_t flags, void *context);
void startThread(thread_mode_change_cb_t callback);


#endif
```
